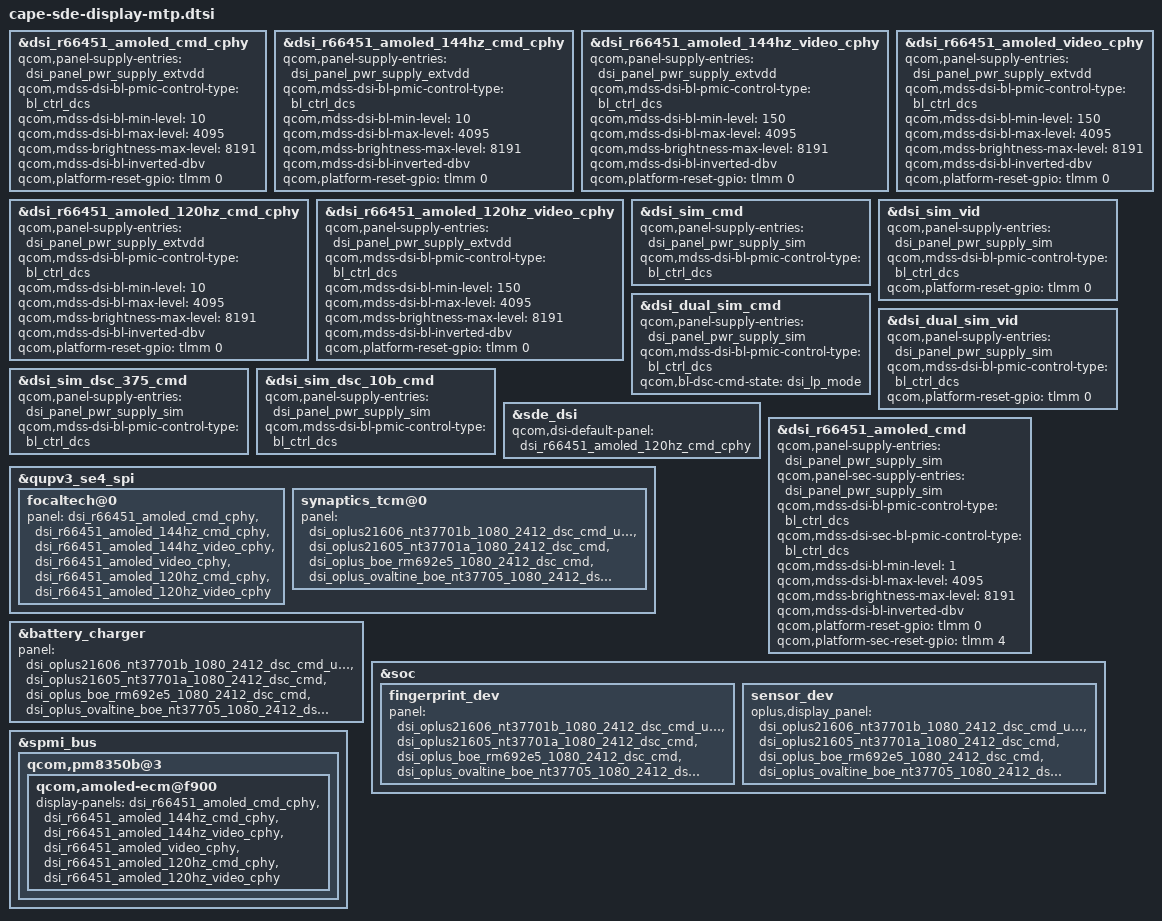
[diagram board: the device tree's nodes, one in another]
#include "cape-sde-display.dtsi"

&dsi_r66451_amoled_cmd_cphy {
	qcom,panel-supply-entries = <&dsi_panel_pwr_supply_extvdd>;
	qcom,mdss-dsi-bl-pmic-control-type = "bl_ctrl_dcs";
	qcom,mdss-dsi-bl-min-level = <10>;
	qcom,mdss-dsi-bl-max-level = <4095>;
	qcom,mdss-brightness-max-level = <8191>;
	qcom,mdss-dsi-bl-inverted-dbv;
	qcom,platform-reset-gpio = <&tlmm 0 0>;
};

&dsi_r66451_amoled_144hz_cmd_cphy {
	qcom,panel-supply-entries = <&dsi_panel_pwr_supply_extvdd>;
	qcom,mdss-dsi-bl-pmic-control-type = "bl_ctrl_dcs";
	qcom,mdss-dsi-bl-min-level = <10>;
	qcom,mdss-dsi-bl-max-level = <4095>;
	qcom,mdss-brightness-max-level = <8191>;
	qcom,mdss-dsi-bl-inverted-dbv;
	qcom,platform-reset-gpio = <&tlmm 0 0>;
};

&dsi_r66451_amoled_144hz_video_cphy {
	qcom,panel-supply-entries = <&dsi_panel_pwr_supply_extvdd>;
	qcom,mdss-dsi-bl-pmic-control-type = "bl_ctrl_dcs";
	qcom,mdss-dsi-bl-min-level = <150>;
	qcom,mdss-dsi-bl-max-level = <4095>;
	qcom,mdss-brightness-max-level = <8191>;
	qcom,mdss-dsi-bl-inverted-dbv;
	qcom,platform-reset-gpio = <&tlmm 0 0>;
};

&dsi_r66451_amoled_video_cphy {
	qcom,panel-supply-entries = <&dsi_panel_pwr_supply_extvdd>;
	qcom,mdss-dsi-bl-pmic-control-type = "bl_ctrl_dcs";
	qcom,mdss-dsi-bl-min-level = <150>;
	qcom,mdss-dsi-bl-max-level = <4095>;
	qcom,mdss-brightness-max-level = <8191>;
	qcom,mdss-dsi-bl-inverted-dbv;
	qcom,platform-reset-gpio = <&tlmm 0 0>;
};

&dsi_r66451_amoled_120hz_cmd_cphy {
	qcom,panel-supply-entries = <&dsi_panel_pwr_supply_extvdd>;
	qcom,mdss-dsi-bl-pmic-control-type = "bl_ctrl_dcs";
	qcom,mdss-dsi-bl-min-level = <10>;
	qcom,mdss-dsi-bl-max-level = <4095>;
	qcom,mdss-brightness-max-level = <8191>;
	qcom,mdss-dsi-bl-inverted-dbv;
	qcom,platform-reset-gpio = <&tlmm 0 0>;
};

&dsi_r66451_amoled_120hz_video_cphy {
	qcom,panel-supply-entries = <&dsi_panel_pwr_supply_extvdd>;
	qcom,mdss-dsi-bl-pmic-control-type = "bl_ctrl_dcs";
	qcom,mdss-dsi-bl-min-level = <150>;
	qcom,mdss-dsi-bl-max-level = <4095>;
	qcom,mdss-brightness-max-level = <8191>;
	qcom,mdss-dsi-bl-inverted-dbv;
	qcom,platform-reset-gpio = <&tlmm 0 0>;
};

&dsi_sim_cmd {
	qcom,panel-supply-entries = <&dsi_panel_pwr_supply_sim>;
	qcom,mdss-dsi-bl-pmic-control-type = "bl_ctrl_dcs";
};

&dsi_sim_vid {
	qcom,panel-supply-entries = <&dsi_panel_pwr_supply_sim>;
	qcom,mdss-dsi-bl-pmic-control-type = "bl_ctrl_dcs";
	qcom,platform-reset-gpio = <&tlmm 0 0>;
};

&dsi_dual_sim_cmd {
	qcom,panel-supply-entries = <&dsi_panel_pwr_supply_sim>;
	qcom,mdss-dsi-bl-pmic-control-type = "bl_ctrl_dcs";
	qcom,bl-dsc-cmd-state = "dsi_lp_mode";
};

&dsi_dual_sim_vid {
	qcom,panel-supply-entries = <&dsi_panel_pwr_supply_sim>;
	qcom,mdss-dsi-bl-pmic-control-type = "bl_ctrl_dcs";
	qcom,platform-reset-gpio = <&tlmm 0 0>;
};

&dsi_sim_dsc_375_cmd {
	qcom,panel-supply-entries = <&dsi_panel_pwr_supply_sim>;
	qcom,mdss-dsi-bl-pmic-control-type = "bl_ctrl_dcs";
};

&dsi_sim_dsc_10b_cmd {
	qcom,panel-supply-entries = <&dsi_panel_pwr_supply_sim>;
	qcom,mdss-dsi-bl-pmic-control-type = "bl_ctrl_dcs";
};

&sde_dsi {
	qcom,dsi-default-panel = <&dsi_r66451_amoled_120hz_cmd_cphy>;
};

&dsi_r66451_amoled_cmd {
	qcom,panel-supply-entries = <&dsi_panel_pwr_supply_sim>;
	qcom,panel-sec-supply-entries = <&dsi_panel_pwr_supply_sim>;
	qcom,mdss-dsi-bl-pmic-control-type = "bl_ctrl_dcs";
	qcom,mdss-dsi-sec-bl-pmic-control-type = "bl_ctrl_dcs";
	qcom,mdss-dsi-bl-min-level = <1>;
	qcom,mdss-dsi-bl-max-level = <4095>;
	qcom,mdss-brightness-max-level = <8191>;
	qcom,mdss-dsi-bl-inverted-dbv;
	qcom,platform-reset-gpio = <&tlmm 0 0>;
	qcom,platform-sec-reset-gpio = <&tlmm 4 0>;
};

&qupv3_se4_spi {
	focaltech@0 {
		panel = <&dsi_r66451_amoled_cmd_cphy
			&dsi_r66451_amoled_144hz_cmd_cphy
			&dsi_r66451_amoled_144hz_video_cphy
			&dsi_r66451_amoled_video_cphy
			&dsi_r66451_amoled_120hz_cmd_cphy
			&dsi_r66451_amoled_120hz_video_cphy>;
	};
	synaptics_tcm@0{
		panel = <&dsi_oplus21606_nt37701b_1080_2412_dsc_cmd_udc
			&dsi_oplus21605_nt37701a_1080_2412_dsc_cmd
			&dsi_oplus_boe_rm692e5_1080_2412_dsc_cmd
			&dsi_oplus_ovaltine_boe_nt37705_1080_2412_dsc_cmd>;
	};
};

//#ifdef OPLUS_FEATURE_CHG_BASIC
//NOTE:Everytime if LCD model is changed,here needs to be modified
&battery_charger {
	panel = <&dsi_oplus21606_nt37701b_1080_2412_dsc_cmd_udc &dsi_oplus21605_nt37701a_1080_2412_dsc_cmd &dsi_oplus_boe_rm692e5_1080_2412_dsc_cmd &dsi_oplus_ovaltine_boe_nt37705_1080_2412_dsc_cmd>;
};
//#endif
//#ifdef OPLUS_FEATURE_UFF_FINGERPRINT
&soc {
        fingerprint_dev {
            panel = <&dsi_oplus21606_nt37701b_1080_2412_dsc_cmd_udc &dsi_oplus21605_nt37701a_1080_2412_dsc_cmd &dsi_oplus_boe_rm692e5_1080_2412_dsc_cmd &dsi_oplus_ovaltine_boe_nt37705_1080_2412_dsc_cmd>;
        };
};
//#endif /*OPLUS_FEATURE_UFF_FINGERPRINT*/
&soc {
        sensor_dev {
                oplus,display_panel = <&dsi_oplus21606_nt37701b_1080_2412_dsc_cmd_udc &dsi_oplus21605_nt37701a_1080_2412_dsc_cmd &dsi_oplus_boe_rm692e5_1080_2412_dsc_cmd &dsi_oplus_ovaltine_boe_nt37705_1080_2412_dsc_cmd>;
        };
};
&spmi_bus {
	qcom,pm8350b@3 {
		qcom,amoled-ecm@f900 {
			display-panels = <&dsi_r66451_amoled_cmd_cphy
					&dsi_r66451_amoled_144hz_cmd_cphy
					&dsi_r66451_amoled_144hz_video_cphy
					&dsi_r66451_amoled_video_cphy
					&dsi_r66451_amoled_120hz_cmd_cphy
					&dsi_r66451_amoled_120hz_video_cphy>;
		};
	};
};
